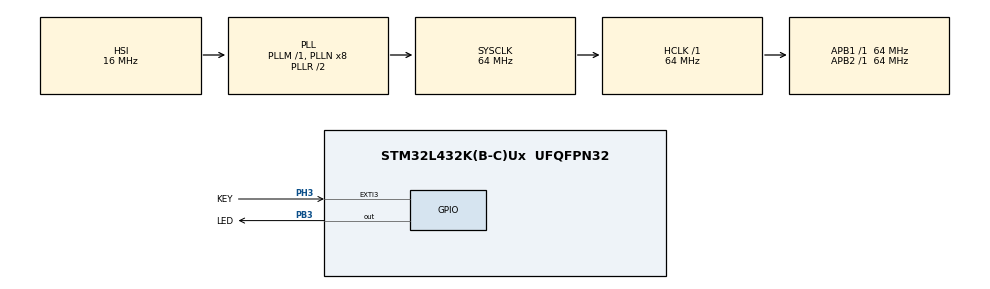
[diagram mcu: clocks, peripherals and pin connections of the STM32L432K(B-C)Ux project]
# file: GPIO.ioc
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Mcu.Family=STM32L4
Mcu.Name=STM32L432K(B-C)Ux
Mcu.Package=UFQFPN32
NVIC.EXTI3_IRQn=true\:0\:0\:false\:false\:true\:true\:true\:true
NVIC.PriorityGroup=NVIC_PRIORITYGROUP_4
PA13\ (JTMS-SWDIO).Mode=Serial_Wire
PA13\ (JTMS-SWDIO).Signal=SYS_JTMS-SWDIO
PA14\ (JTCK-SWCLK).Mode=Serial_Wire
PA14\ (JTCK-SWCLK).Signal=SYS_JTCK-SWCLK
PB3\ (JTDO-TRACESWO).GPIO_Label=LED
PB3\ (JTDO-TRACESWO).Signal=GPIO_Output
PH3-BOOT0.GPIO_Label=KEY
PH3-BOOT0.GPIO_ModeDefaultEXTI=GPIO_MODE_IT_RISING
PH3-BOOT0.GPIO_PuPd=GPIO_PULLDOWN
PH3-BOOT0.Signal=GPXTI3
ProjectManager.HeapSize=0x200
ProjectManager.StackSize=0x400
ProjectManager.TargetToolchain=MDK-ARM V5.32
RCC.ADCFreq_Value=64000000
RCC.AHBFreq_Value=64000000
RCC.APB1Freq_Value=64000000
RCC.APB1TimFreq_Value=64000000
RCC.APB2Freq_Value=64000000
RCC.APB2TimFreq_Value=64000000
RCC.CortexFreq_Value=64000000
RCC.HCLKFreq_Value=64000000
RCC.HSE_VALUE=8000000
RCC.HSI48_VALUE=48000000
RCC.HSI_VALUE=16000000
RCC.LSE_VALUE=32768
RCC.MSI_VALUE=4000000
RCC.PLLSourceVirtual=RCC_PLLSOURCE_HSI
RCC.SYSCLKFreq_VALUE=64000000
RCC.SYSCLKSource=RCC_SYSCLKSOURCE_PLLCLK
RCC.USBFreq_Value=64000000
RCC.VCOOutputFreq_Value=128000000
board=custom

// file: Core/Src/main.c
/* USER CODE BEGIN Header */
/**
  ******************************************************************************
  * @file           : main.c
  * @brief          : Main program body
  ******************************************************************************
  * @attention
  *
  * Copyright (c) 2024 STMicroelectronics.
  * All rights reserved.
  *
  * This software is licensed under terms that can be found in the LICENSE file
  * in the root directory of this software component.
  * If no LICENSE file comes with this software, it is provided AS-IS.
  *
  ******************************************************************************
  */
/* USER CODE END Header */
#include "main.h"
#include "gpio.h"

void SystemClock_Config(void);

/* USER CODE BEGIN 0 */
void HAL_GPIO_EXTI_Callback(uint16_t GPIO_Pin)
{
		static uint32_t tick = 0;

    // non-blocking debouncing of buttons
		if(HAL_GetTick() -  tick < 300)
				return;

		tick = HAL_GetTick();

		if(GPIO_Pin == KEY_Pin)
				HAL_GPIO_TogglePin(LED_GPIO_Port, LED_Pin);
}
/* USER CODE END 0 */

int main(void)
{

  /* MCU Configuration--------------------------------------------------------*/

  /* Reset of all peripherals, Initializes the Flash interface and the Systick. */
  HAL_Init();

  /* Configure the system clock */
  SystemClock_Config();

  /* Initialize all configured peripherals */
  MX_GPIO_Init();

  /* Infinite loop */
  while (1)
  {

  }
}

void SystemClock_Config(void)
{
  RCC_OscInitTypeDef RCC_OscInitStruct = {0};
  RCC_ClkInitTypeDef RCC_ClkInitStruct = {0};

  /** Configure the main internal regulator output voltage
  */
  if (HAL_PWREx_ControlVoltageScaling(PWR_REGULATOR_VOLTAGE_SCALE1) != HAL_OK)
  {
    Error_Handler();
  }

  /** Initializes the RCC Oscillators according to the specified parameters
  * in the RCC_OscInitTypeDef structure.
  */
  RCC_OscInitStruct.OscillatorType = RCC_OSCILLATORTYPE_HSI;
  RCC_OscInitStruct.HSIState = RCC_HSI_ON;
  RCC_OscInitStruct.HSICalibrationValue = RCC_HSICALIBRATION_DEFAULT;
  RCC_OscInitStruct.PLL.PLLState = RCC_PLL_ON;
  RCC_OscInitStruct.PLL.PLLSource = RCC_PLLSOURCE_HSI;
  RCC_OscInitStruct.PLL.PLLM = 1;
  RCC_OscInitStruct.PLL.PLLN = 8;
  RCC_OscInitStruct.PLL.PLLP = RCC_PLLP_DIV7;
  RCC_OscInitStruct.PLL.PLLQ = RCC_PLLQ_DIV2;
  RCC_OscInitStruct.PLL.PLLR = RCC_PLLR_DIV2;
  if (HAL_RCC_OscConfig(&RCC_OscInitStruct) != HAL_OK)
  {
    Error_Handler();
  }

  /** Initializes the CPU, AHB and APB buses clocks
  */
  RCC_ClkInitStruct.ClockType = RCC_CLOCKTYPE_HCLK|RCC_CLOCKTYPE_SYSCLK
                              |RCC_CLOCKTYPE_PCLK1|RCC_CLOCKTYPE_PCLK2;
  RCC_ClkInitStruct.SYSCLKSource = RCC_SYSCLKSOURCE_PLLCLK;
  RCC_ClkInitStruct.AHBCLKDivider = RCC_SYSCLK_DIV1;
  RCC_ClkInitStruct.APB1CLKDivider = RCC_HCLK_DIV1;
  RCC_ClkInitStruct.APB2CLKDivider = RCC_HCLK_DIV1;

  if (HAL_RCC_ClockConfig(&RCC_ClkInitStruct, FLASH_LATENCY_3) != HAL_OK)
  {
    Error_Handler();
  }
}

void Error_Handler(void)
{
  __disable_irq();
  while (1)
  {
  }
}
